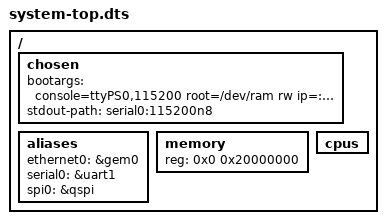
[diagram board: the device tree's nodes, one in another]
/*
 * CAUTION: This file is automatically generated by Xilinx.
 * Version:  
 * Today is: Fri Nov 08 21:58:53 2019
*/


/dts-v1/;
/include/ "zynq-7000.dtsi"
/include/ "pl.dtsi"
/include/ "pcw.dtsi"
/ {
	chosen {
		bootargs = "console=ttyPS0,115200 root=/dev/ram rw ip=:::::eth0:dhcp earlyprintk earlycon";
		stdout-path = "serial0:115200n8";
	};
	aliases {
		ethernet0 = &gem0;
		serial0 = &uart1;
		spi0 = &qspi;
	};
	memory {
		device_type = "memory";
		reg = <0x0 0x20000000>;
	};
	cpus {
	};
};
